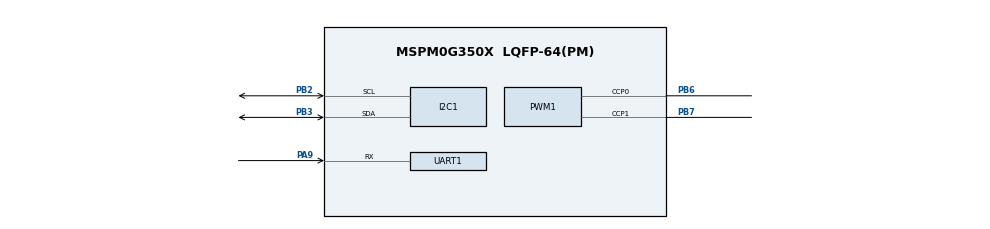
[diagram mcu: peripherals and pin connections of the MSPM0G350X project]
/**
 * @cliArgs --device "MSPM0G350X" --part "Default" --package "LQFP-64(PM)" --product "mspm0_sdk@2.05.01.01"
 * @versions {"tool":"1.23.1+4034"}
 */

/**
 * Import the modules used in this configuration.
 */
const GPIO    = scripting.addModule("/ti/driverlib/GPIO", {}, false);
const GPIO1   = GPIO.addInstance();
const GPIO2   = GPIO.addInstance();
const GPIO3   = GPIO.addInstance();
const GPIO4   = GPIO.addInstance();
const GPIO5   = GPIO.addInstance();
const GPIO6   = GPIO.addInstance();
const I2C     = scripting.addModule("/ti/driverlib/I2C", {}, false);
const I2C1    = I2C.addInstance();
const PWM     = scripting.addModule("/ti/driverlib/PWM", {}, false);
const PWM1    = PWM.addInstance();
const SYSCTL  = scripting.addModule("/ti/driverlib/SYSCTL");
const SYSTICK = scripting.addModule("/ti/driverlib/SYSTICK");
const TIMER   = scripting.addModule("/ti/driverlib/TIMER", {}, false);
const TIMER1  = TIMER.addInstance();
const UART    = scripting.addModule("/ti/driverlib/UART", {}, false);
const UART1   = UART.addInstance();

/**
 * Write custom configuration values to the imported modules.
 */
const divider6       = system.clockTree["PLL_CLK2X_DIV"];
divider6.divideValue = 4;

const divider7       = system.clockTree["PLL_PDIV"];
divider7.divideValue = 2;

const divider9       = system.clockTree["UDIV"];
divider9.divideValue = 2;

const multiplier2         = system.clockTree["PLL_QDIV"];
multiplier2.multiplyValue = 10;

const mux8       = system.clockTree["HSCLKMUX"];
mux8.inputSelect = "HSCLKMUX_SYSPLL2X";

GPIO1.$name                          = "AIN";
GPIO1.associatedPins.create(2);
GPIO1.associatedPins[0].$name        = "AIN1";
GPIO1.associatedPins[0].assignedPort = "PORTB";
GPIO1.associatedPins[0].assignedPin  = "20";
GPIO1.associatedPins[0].initialValue = "SET";
GPIO1.associatedPins[1].$name        = "AIN2";
GPIO1.associatedPins[1].assignedPin  = "24";
GPIO1.associatedPins[1].assignedPort = "PORTB";

const Board = scripting.addModule("/ti/driverlib/Board", {}, false);

GPIO2.$name                          = "BIN";
GPIO2.associatedPins.create(2);
GPIO2.associatedPins[0].$name        = "BIN1";
GPIO2.associatedPins[0].assignedPort = "PORTB";
GPIO2.associatedPins[0].assignedPin  = "18";
GPIO2.associatedPins[0].initialValue = "SET";
GPIO2.associatedPins[1].$name        = "BIN2";
GPIO2.associatedPins[1].assignedPort = "PORTB";
GPIO2.associatedPins[1].assignedPin  = "19";

GPIO3.$name                          = "STBY";
GPIO3.associatedPins[0].$name        = "ebl";
GPIO3.associatedPins[0].initialValue = "SET";
GPIO3.associatedPins[0].assignedPort = "PORTB";
GPIO3.associatedPins[0].assignedPin  = "16";

GPIO4.$name                               = "Encoder_Left";
GPIO4.associatedPins.create(2);
GPIO4.associatedPins[0].direction         = "INPUT";
GPIO4.associatedPins[0].assignedPort      = "PORTA";
GPIO4.associatedPins[0].assignedPin       = "12";
GPIO4.associatedPins[0].interruptEn       = true;
GPIO4.associatedPins[0].interruptPriority = "0";
GPIO4.associatedPins[0].polarity          = "RISE";
GPIO4.associatedPins[0].$name             = "front_l";
GPIO4.associatedPins[1].direction         = "INPUT";
GPIO4.associatedPins[1].assignedPort      = "PORTA";
GPIO4.associatedPins[1].assignedPin       = "13";
GPIO4.associatedPins[1].$name             = "back_l";

GPIO5.$name                               = "Encoder_Right";
GPIO5.associatedPins.create(2);
GPIO5.associatedPins[0].$name             = "front_r";
GPIO5.associatedPins[0].direction         = "INPUT";
GPIO5.associatedPins[0].internalResistor  = "PULL_UP";
GPIO5.associatedPins[0].assignedPort      = "PORTA";
GPIO5.associatedPins[0].assignedPin       = "15";
GPIO5.associatedPins[0].interruptEn       = true;
GPIO5.associatedPins[0].interruptPriority = "0";
GPIO5.associatedPins[0].polarity          = "RISE";
GPIO5.associatedPins[1].$name             = "back_r";
GPIO5.associatedPins[1].direction         = "INPUT";
GPIO5.associatedPins[1].assignedPort      = "PORTA";
GPIO5.associatedPins[1].assignedPin       = "24";

GPIO6.$name                              = "Gray";
GPIO6.associatedPins.create(8);
GPIO6.associatedPins[0].$name            = "PIN_0";
GPIO6.associatedPins[0].direction        = "INPUT";
GPIO6.associatedPins[0].assignedPort     = "PORTB";
GPIO6.associatedPins[0].assignedPin      = "12";
GPIO6.associatedPins[0].internalResistor = "PULL_UP";
GPIO6.associatedPins[1].$name            = "PIN_1";
GPIO6.associatedPins[1].direction        = "INPUT";
GPIO6.associatedPins[1].assignedPort     = "PORTB";
GPIO6.associatedPins[1].assignedPin      = "17";
GPIO6.associatedPins[1].internalResistor = "PULL_UP";
GPIO6.associatedPins[2].$name            = "PIN_2";
GPIO6.associatedPins[2].direction        = "INPUT";
GPIO6.associatedPins[2].assignedPort     = "PORTB";
GPIO6.associatedPins[2].assignedPin      = "4";
GPIO6.associatedPins[2].internalResistor = "PULL_UP";
GPIO6.associatedPins[3].$name            = "PIN_3";
GPIO6.associatedPins[3].direction        = "INPUT";
GPIO6.associatedPins[3].internalResistor = "PULL_UP";
GPIO6.associatedPins[3].assignedPort     = "PORTB";
GPIO6.associatedPins[3].assignedPin      = "1";
GPIO6.associatedPins[4].$name            = "PIN_4";
GPIO6.associatedPins[4].direction        = "INPUT";
GPIO6.associatedPins[4].internalResistor = "PULL_UP";
GPIO6.associatedPins[4].assignedPort     = "PORTA";
GPIO6.associatedPins[4].assignedPin      = "28";
GPIO6.associatedPins[5].$name            = "PIN_5";
GPIO6.associatedPins[5].direction        = "INPUT";
GPIO6.associatedPins[5].assignedPort     = "PORTA";
GPIO6.associatedPins[5].assignedPin      = "31";
GPIO6.associatedPins[5].internalResistor = "PULL_UP";
GPIO6.associatedPins[6].$name            = "PIN_6";
GPIO6.associatedPins[6].direction        = "INPUT";
GPIO6.associatedPins[6].internalResistor = "PULL_UP";
GPIO6.associatedPins[6].assignedPort     = "PORTB";
GPIO6.associatedPins[6].assignedPin      = "15";
GPIO6.associatedPins[7].$name            = "PIN_7";
GPIO6.associatedPins[7].assignedPort     = "PORTB";
GPIO6.associatedPins[7].assignedPin      = "13";
GPIO6.associatedPins[7].direction        = "INPUT";
GPIO6.associatedPins[7].internalResistor = "PULL_UP";

I2C1.$name                             = "I2C_OLED";
I2C1.basicEnableController             = true;
I2C1.basicControllerStandardBusSpeed   = "Fast";
I2C1.peripheral.sdaPin.$assign         = "PB3";
I2C1.peripheral.sclPin.$assign         = "PB2";
I2C1.sdaPinConfig.$name                = "ti_driverlib_gpio_GPIOPinGeneric0";
I2C1.sdaPinConfig.hideOutputInversion  = scripting.forceWrite(false);
I2C1.sdaPinConfig.onlyInternalResistor = scripting.forceWrite(false);
I2C1.sdaPinConfig.passedPeripheralType = scripting.forceWrite("Digital");
I2C1.sclPinConfig.hideOutputInversion  = scripting.forceWrite(false);
I2C1.sclPinConfig.onlyInternalResistor = scripting.forceWrite(false);
I2C1.sclPinConfig.passedPeripheralType = scripting.forceWrite("Digital");
I2C1.sclPinConfig.$name                = "ti_driverlib_gpio_GPIOPinGeneric2";

PWM1.$name                              = "PWM_MOTOR";
PWM1.timerCount                         = 8000;
PWM1.timerStartTimer                    = true;
PWM1.peripheral.ccp0Pin.$assign         = "PB6";
PWM1.peripheral.ccp1Pin.$assign         = "PB7";
PWM1.PWM_CHANNEL_0.$name                = "ti_driverlib_pwm_PWMTimerCC0";
PWM1.PWM_CHANNEL_0.dutyCycle            = 80;
PWM1.PWM_CHANNEL_0.initVal              = "HIGH";
PWM1.PWM_CHANNEL_1.$name                = "ti_driverlib_pwm_PWMTimerCC1";
PWM1.PWM_CHANNEL_1.dutyCycle            = 50;
PWM1.ccp0PinConfig.direction            = scripting.forceWrite("OUTPUT");
PWM1.ccp0PinConfig.hideOutputInversion  = scripting.forceWrite(false);
PWM1.ccp0PinConfig.onlyInternalResistor = scripting.forceWrite(false);
PWM1.ccp0PinConfig.passedPeripheralType = scripting.forceWrite("Digital");
PWM1.ccp0PinConfig.$name                = "ti_driverlib_gpio_GPIOPinGeneric3";
PWM1.ccp1PinConfig.direction            = scripting.forceWrite("OUTPUT");
PWM1.ccp1PinConfig.hideOutputInversion  = scripting.forceWrite(false);
PWM1.ccp1PinConfig.onlyInternalResistor = scripting.forceWrite(false);
PWM1.ccp1PinConfig.passedPeripheralType = scripting.forceWrite("Digital");
PWM1.ccp1PinConfig.$name                = "ti_driverlib_gpio_GPIOPinGeneric4";

SYSCTL.forceDefaultClkConfig = true;
SYSCTL.clockTreeEn           = true;

SYSTICK.interruptEnable   = true;
SYSTICK.interruptPriority = "0";
SYSTICK.periodEnable      = true;
SYSTICK.period            = 80000;
SYSTICK.systickEnable     = true;

TIMER1.timerPeriod        = "10 ms";
TIMER1.timerClkDiv        = 8;
TIMER1.timerClkPrescale   = 256;
TIMER1.$name              = "TIMER_10ms";
TIMER1.interrupts         = ["ZERO"];
TIMER1.interruptPriority  = "0";
TIMER1.timerStartTimer    = true;
TIMER1.timerMode          = "PERIODIC";
TIMER1.peripheral.$assign = "TIMG0";

UART1.$name                            = "UART_WIT";
UART1.targetBaudRate                   = 115200;
UART1.direction                        = "RX";
UART1.enableFIFO                       = true;
UART1.rxTimeoutValue                   = 1;
UART1.enabledInterrupts                = ["RX_TIMEOUT_ERROR"];
UART1.enabledDMARXTriggers             = "DL_UART_DMA_INTERRUPT_RX";
UART1.rxPinConfig.hideOutputInversion  = scripting.forceWrite(false);
UART1.rxPinConfig.onlyInternalResistor = scripting.forceWrite(false);
UART1.rxPinConfig.passedPeripheralType = scripting.forceWrite("Digital");
UART1.rxPinConfig.$name                = "ti_driverlib_gpio_GPIOPinGeneric1";
UART1.peripheral.rxPin.$assign         = "PA9";
UART1.DMA_CHANNEL_RX.$name             = "DMA_WIT";
UART1.DMA_CHANNEL_RX.addressMode       = "f2b";
UART1.DMA_CHANNEL_RX.srcLength         = "BYTE";
UART1.DMA_CHANNEL_RX.dstLength         = "BYTE";

/**
 * Pinmux solution for unlocked pins/peripherals. This ensures that minor changes to the automatic solver in a future
 * version of the tool will not impact the pinmux you originally saw.  These lines can be completely deleted in order to
 * re-solve from scratch.
 */
GPIO1.associatedPins[0].pin.$suggestSolution     = "PB20";
GPIO1.associatedPins[1].pin.$suggestSolution     = "PB24";
Board.peripheral.$suggestSolution                = "DEBUGSS";
Board.peripheral.swclkPin.$suggestSolution       = "PA20";
Board.peripheral.swdioPin.$suggestSolution       = "PA19";
GPIO2.associatedPins[0].pin.$suggestSolution     = "PB18";
GPIO2.associatedPins[1].pin.$suggestSolution     = "PB19";
GPIO3.associatedPins[0].pin.$suggestSolution     = "PB16";
GPIO4.associatedPins[0].pin.$suggestSolution     = "PA12";
GPIO4.associatedPins[1].pin.$suggestSolution     = "PA13";
GPIO5.associatedPins[0].pin.$suggestSolution     = "PA15";
GPIO5.associatedPins[1].pin.$suggestSolution     = "PA24";
GPIO6.associatedPins[0].pin.$suggestSolution     = "PB12";
GPIO6.associatedPins[1].pin.$suggestSolution     = "PB17";
GPIO6.associatedPins[2].pin.$suggestSolution     = "PB4";
GPIO6.associatedPins[3].pin.$suggestSolution     = "PB1";
GPIO6.associatedPins[4].pin.$suggestSolution     = "PA28";
GPIO6.associatedPins[5].pin.$suggestSolution     = "PA31";
GPIO6.associatedPins[6].pin.$suggestSolution     = "PB15";
GPIO6.associatedPins[7].pin.$suggestSolution     = "PB13";
I2C1.peripheral.$suggestSolution                 = "I2C1";
PWM1.peripheral.$suggestSolution                 = "TIMG6";
UART1.peripheral.$suggestSolution                = "UART1";
UART1.DMA_CHANNEL_RX.peripheral.$suggestSolution = "DMA_CH0";
